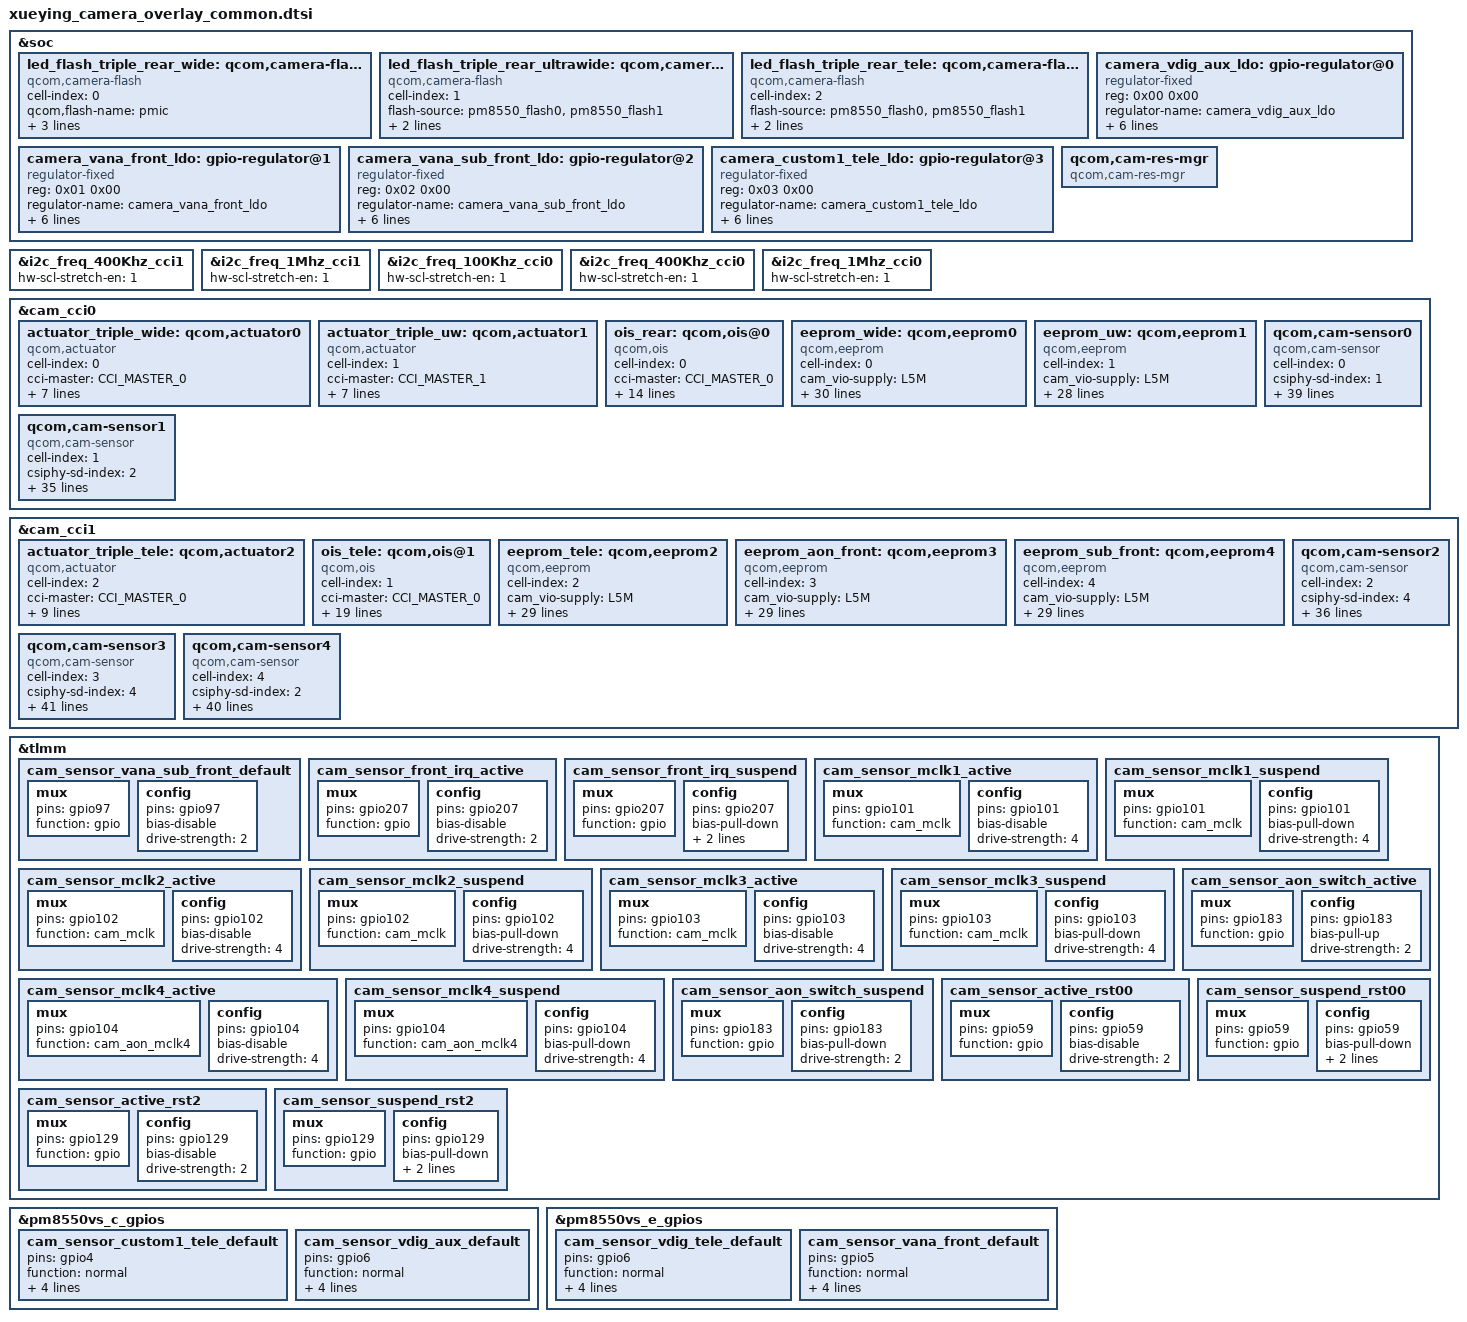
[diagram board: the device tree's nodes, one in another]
#include <dt-bindings/msm-camera.h>

&soc {
	led_flash_triple_rear_wide: qcom,camera-flash0 {
		cell-index = <0>;
		compatible = "qcom,camera-flash";
		qcom,flash-name = "pmic";
		flash-source = <&pm8550_flash0 &pm8550_flash1>;
		torch-source = <&pm8550_torch0 &pm8550_torch1>;
		switch-source = <&pm8550_switch2>;
		status = "ok";
	};

	led_flash_triple_rear_ultrawide: qcom,camera-flash1 {
		cell-index = <1>;
		compatible = "qcom,camera-flash";
		flash-source = <&pm8550_flash0 &pm8550_flash1>;
		torch-source = <&pm8550_torch0 &pm8550_torch1>;
		switch-source = <&pm8550_switch2>;
		status = "ok";
	};

	led_flash_triple_rear_tele: qcom,camera-flash2 {
		cell-index = <2>;
		compatible = "qcom,camera-flash";
		flash-source = <&pm8550_flash0 &pm8550_flash1>;
		torch-source = <&pm8550_torch0 &pm8550_torch1>;
		switch-source = <&pm8550_switch2>;
		status = "ok";
	};

	camera_vdig_aux_ldo: gpio-regulator@0 {
		compatible = "regulator-fixed";
		reg = <0x00 0x00>;
		regulator-name = "camera_vdig_aux_ldo";
		regulator-min-microvolt = <1120000>;
		regulator-max-microvolt = <1120000>;
		regulator-enable-ramp-delay = <135>;
		enable-active-high;
		gpio = <&pm8550vs_c_gpios 6 0>;
		pinctrl-names = "default";
		pinctrl-0 = <&cam_sensor_vdig_aux_default>;
		//vin-supply = <&S6G>;
	};

	camera_vana_front_ldo: gpio-regulator@1 {
		compatible = "regulator-fixed";
		reg = <0x01 0x00>;
		regulator-name = "camera_vana_front_ldo";
		regulator-min-microvolt = <2800000>;
		regulator-max-microvolt = <2800000>;
		regulator-enable-ramp-delay = <135>;
		enable-active-high;
		gpio = <&pm8550vs_e_gpios 5 0>;
		pinctrl-names = "default";
		pinctrl-0 = <&cam_sensor_vana_front_default>;
	};

	camera_vana_sub_front_ldo: gpio-regulator@2 {
		compatible = "regulator-fixed";
		reg = <0x02 0x00>;
		regulator-name = "camera_vana_sub_front_ldo";
		regulator-min-microvolt = <2800000>;
		regulator-max-microvolt = <2800000>;
		regulator-enable-ramp-delay = <135>;
		enable-active-high;
		gpio = <&tlmm 97 0>;
		pinctrl-names = "default";
		pinctrl-0 = <&cam_sensor_vana_sub_front_default>;
	};


    camera_custom1_tele_ldo: gpio-regulator@3 {
		compatible = "regulator-fixed";
		reg = <0x03 0x00>;
		regulator-name = "camera_custom1_tele_ldo";
		regulator-min-microvolt = <2800000>;
		regulator-max-microvolt = <2800000>;
		regulator-enable-ramp-delay = <135>;
		enable-active-high;
		gpio = <&pm8550vs_c_gpios 4 0>;
		pinctrl-names = "default";
		pinctrl-0 = <&cam_sensor_custom1_tele_default>;
	};

	qcom,cam-res-mgr {
		compatible = "qcom,cam-res-mgr";
		status = "ok";
	};
};


&i2c_freq_400Khz_cci1 {
    hw-scl-stretch-en = <1>;
};

&i2c_freq_1Mhz_cci1 {
    hw-scl-stretch-en = <1>;
};

&i2c_freq_100Khz_cci0 {
    hw-scl-stretch-en = <1>;
};

&i2c_freq_400Khz_cci0 {
    hw-scl-stretch-en = <1>;
};

&i2c_freq_1Mhz_cci0 {
    hw-scl-stretch-en = <1>;
};

&cam_cci0 {
	actuator_triple_wide: qcom,actuator0 {
		cell-index = <0>;
		compatible = "qcom,actuator";
		cci-master = <CCI_MASTER_0>;
		cam_vio-supply = <&L5M>;
		cam_vaf-supply = <&L6M>;
		regulator-names = "cam_vio", "cam_vaf";
		rgltr-cntrl-support;
		rgltr-min-voltage = <1800000 3000000>;
		rgltr-max-voltage = <1800000 3000000>;
		rgltr-load-current = <600000 300000>;
		status = "ok";
	};

	actuator_triple_uw: qcom,actuator1 {
		cell-index = <1>;
		compatible = "qcom,actuator";
		cci-master = <CCI_MASTER_1>;
		cam_vio-supply = <&L5M>;
		cam_vaf-supply = <&L6N>;
		regulator-names = "cam_vio", "cam_vaf";
		rgltr-cntrl-support;
		rgltr-min-voltage = <1800000 2800000>;
		rgltr-max-voltage = <1800000 2800000>;
		rgltr-load-current = <600000 300000>;
		status = "ok";
	};

	ois_rear: qcom,ois@0{
		cell-index = <0>;
		compatible = "qcom,ois";
		cci-master = <CCI_MASTER_0>;
		cam_vio-supply = <&L5M>;
		cam_v_custom2-supply = <&L7M>;
		cam_vaf-supply = <&L6M>;
		regulator-names = "cam_vio","cam_v_custom1", "cam_vaf";
		rgltr-cntrl-support;
		rgltr-min-voltage = <1800000 3000000 3000000>;
		rgltr-max-voltage = <1800000 3000000 3000000>;
		rgltr-load-current = <600000 600000 300000>;
		ois_gyro,position=<3>;
		ois_gyro,type=<3>;
		ois,type=<0>;
		ois,name="dw9828";
		ois,fw=<1>;
		status = "ok";
	};

	eeprom_wide: qcom,eeprom0 {
		cell-index = <0>;
		compatible = "qcom,eeprom";
		cam_vio-supply = <&L5M>;
		cam_vdig-supply = <&L1M>;
		cam_vana-supply = <&L3M>;
		cam_v_custom1-supply = <&L4M>;
		cam_vaf-supply = <&L6M>;
		cam_v_custom2-supply = <&L7M>;
		cam_clk-supply = <&cam_cc_titan_top_gdsc>;
		regulator-names = "cam_vio", "cam_vana", "cam_v_custom1", "cam_vdig", "cam_vaf",
		                  "cam_v_custom2", "cam_clk";
		rgltr-cntrl-support;
		rgltr-min-voltage = <1800000 2200000 2000000 840000 3000000 3000000 0>;
		rgltr-max-voltage = <1800000 2800000 2000000 920000 3000000 3000000 0>;
		rgltr-load-current = <600000 300000 300000 1200000 300000 600000 0>;
		gpio-no-mux = <0>;
		pinctrl-names = "cam_default", "cam_suspend";
		pinctrl-0 = <&cam_sensor_mclk2_active
			&cam_sensor_active_rst1>;
		pinctrl-1 = <&cam_sensor_mclk2_suspend
			&cam_sensor_suspend_rst1>;
		gpios = <&tlmm 102 0>,
			<&tlmm 117 0>;
		gpio-reset = <1>;
		gpio-req-tbl-num = <0 1>;
		gpio-req-tbl-flags = <1 0>;
		gpio-req-tbl-label = "CAMIF_MCLK2",
					"CAM_RESET1";
		cci-master = <CCI_MASTER_0>;
		clocks = <&camcc CAM_CC_MCLK2_CLK>;
		clock-names = "cam_clk";
		clock-cntl-level = "nominal";
		clock-rates = <19200000>;
		status = "ok";
	};

	eeprom_uw: qcom,eeprom1 {
		cell-index = <1>;
		compatible = "qcom,eeprom";
		cam_vio-supply = <&L5M>;
		cam_vdig-supply = <&L1N>;
		cam_vana-supply = <&L3N>;
		cam_v_custom1-supply = <&L5N>;
		cam_vaf-supply = <&L6N>;
		cam_clk-supply = <&cam_cc_titan_top_gdsc>;
		regulator-names = "cam_vio", "cam_vana", "cam_v_custom1",
			"cam_vdig", "cam_vaf", "cam_clk";
		rgltr-cntrl-support;
		rgltr-min-voltage = <1800000 2904000 1800000 1104000 2800000 0>;
		rgltr-max-voltage = <1800000 2904000 1800000 1104000 2800000 0>;
		rgltr-load-current = <600000 300000 600000 1200000 300000 0>;
		gpio-no-mux = <0>;
		pinctrl-names = "cam_default", "cam_suspend";
		pinctrl-0 = <&cam_sensor_mclk1_active
				 &cam_sensor_active_rst2>;
		pinctrl-1 = <&cam_sensor_mclk1_suspend
				 &cam_sensor_suspend_rst2>;
		gpios = <&tlmm 101 0>,
			<&tlmm 129 0>;
		gpio-reset = <1>;
		gpio-req-tbl-num = <0 1>;
		gpio-req-tbl-flags = <1 0>;
		gpio-req-tbl-label = "CAMIF_MCLK1",
					"CAM_RESET2";
		cci-master = <CCI_MASTER_1>;
		clocks = <&camcc CAM_CC_MCLK1_CLK>;
		clock-names = "cam_clk";
		clock-cntl-level = "nominal";
		clock-rates = <19200000>;
		status = "ok";
	};
    //main camera
	qcom,cam-sensor0 {
		cell-index = <0>;
		compatible = "qcom,cam-sensor";
		csiphy-sd-index = <1>;
		sensor-position-roll = <90>;
		sensor-position-pitch = <0>;
		sensor-position-yaw = <180>;
		eeprom-src = <&eeprom_wide>;
		actuator-src = <&actuator_triple_wide>;
		led-flash-src = <&led_flash_triple_rear_wide>;
		ois-src = <&ois_rear>;
		cam_vio-supply = <&L5M>;
		cam_vdig-supply = <&L1M>;
		cam_vana-supply = <&L3M>;
		cam_v_custom1-supply = <&L4M>;
		cam_vaf-supply = <&L6M>;
		cam_v_custom2-supply = <&L7M>;
		cam_clk-supply = <&cam_cc_titan_top_gdsc>;
		regulator-names = "cam_vio", "cam_vana", "cam_v_custom1", "cam_vdig", "cam_vaf",
		                  "cam_v_custom2", "cam_clk";
		rgltr-cntrl-support;
		rgltr-min-voltage = <1800000 2800000 2000000 840000 3000000 3000000 0>;
		rgltr-max-voltage = <1800000 2800000 2000000 840000 3000000 3000000 0>;
		rgltr-load-current = <600000 300000 300000 1200000 300000 600000 0>;
		gpio-no-mux = <0>;
		pinctrl-names = "cam_default", "cam_suspend";
		pinctrl-0 = <&cam_sensor_mclk2_active
			&cam_sensor_active_rst1>;
		pinctrl-1 = <&cam_sensor_mclk2_suspend
			&cam_sensor_suspend_rst1>;
		gpios = <&tlmm 102 0>,
			<&tlmm 117 0>;
		gpio-reset = <1>;
		gpio-req-tbl-num = <0 1>;
		gpio-req-tbl-flags = <1 0>;
		gpio-req-tbl-label = "CAMIF_MCLK2",
					"CAM_RESET1";
		cci-master = <CCI_MASTER_0>;
		clocks = <&camcc CAM_CC_MCLK2_CLK>;
		clock-names = "cam_clk";
		clock-cntl-level = "nominal";
		clock-rates = <19200000>;
		is-support-laser = <1>;
		status = "ok";
	};
    //wide camera
	qcom,cam-sensor1 {
		cell-index = <1>;
		compatible = "qcom,cam-sensor";
		csiphy-sd-index = <2>;
		sensor-position-roll = <90>;
		sensor-position-pitch = <0>;
		sensor-position-yaw = <180>;
		eeprom-src = <&eeprom_uw>;
		actuator-src = <&actuator_triple_uw>;
		led-flash-src = <&led_flash_triple_rear_ultrawide>;
		cam_vio-supply = <&L5M>;
		cam_vdig-supply = <&L1N>;
		cam_vana-supply = <&L3N>;
		cam_v_custom1-supply = <&L5N>;
		cam_vaf-supply = <&L6N>;
		cam_clk-supply = <&cam_cc_titan_top_gdsc>;
		regulator-names = "cam_vio", "cam_vana", "cam_v_custom1",
			"cam_vdig", "cam_vaf", "cam_clk";
		rgltr-cntrl-support;
		rgltr-min-voltage = <1800000 2904000 1800000 1104000 2800000 0>;
		rgltr-max-voltage = <1800000 2904000 1800000 1104000 2800000 0>;
		rgltr-load-current = <600000 300000 600000 1200000 300000 0>;
		gpio-no-mux = <0>;
		pinctrl-names = "cam_default", "cam_suspend";
		pinctrl-0 = <&cam_sensor_mclk1_active
				 &cam_sensor_active_rst2>;
		pinctrl-1 = <&cam_sensor_mclk1_suspend
				 &cam_sensor_suspend_rst2>;
		gpios = <&tlmm 101 0>,
			<&tlmm 129 0>;
		gpio-reset = <1>;
		gpio-req-tbl-num = <0 1>;
		gpio-req-tbl-flags = <1 0>;
		gpio-req-tbl-label = "CAMIF_MCLK1",
					"CAM_RESET2";
		cci-master = <CCI_MASTER_1>;
		clocks = <&camcc CAM_CC_MCLK1_CLK>;
		clock-names = "cam_clk";
		clock-cntl-level = "nominal";
		clock-rates = <19200000>;
		status = "ok";
	};

};

&cam_cci1 {
	actuator_triple_tele: qcom,actuator2{
		cell-index = <2>;
		compatible = "qcom,actuator";
		cci-master = <CCI_MASTER_0>;
		cam_vio-supply = <&L5M>;
		cam_v_custom1-supply = <&camera_custom1_tele_ldo>;
		cam_vaf-supply = <&L7N>;
		regulator-names = "cam_vio", "cam_v_custom1","cam_vaf";
		rgltr-cntrl-support;
		rgltr-min-voltage = <1800000 2800000 2800000>;
		rgltr-max-voltage = <1800000 2800000 2800000>;
		rgltr-load-current = <600000 600000 600000>;
		status = "ok";
	};

	ois_tele: qcom,ois@1{
		cell-index = <1>;
		compatible = "qcom,ois";
		cci-master = <CCI_MASTER_0>;
		cam_vio-supply = <&L5M>;
		cam_v_custom1-supply = <&camera_custom1_tele_ldo>;
		cam_vaf-supply = <&L7N>;
		regulator-names = "cam_vio", "cam_v_custom1", "cam_vaf";
		rgltr-cntrl-support;
		rgltr-min-voltage = <1800000 2800000 2800000>;
		rgltr-max-voltage = <1800000 2800000 2800000>;
		rgltr-load-current = <600000 600000 600000>;
		ois_gyro,position=<3>;
		ois_gyro,type=<0>;
		ois,type=<1>;
		ois,name="sem1217s";
		ois_module,vendor=<1>;
		ois_actuator,vednor=<2>;
		ois,fw=<1>;
		download,fw=<1>;
		ois_eis_function = <6>;
		actuator_ois_eeprom_merge = <1>;
		status = "ok";
	};

	eeprom_tele: qcom,eeprom2 {
		cell-index = <2>;
		compatible = "qcom,eeprom";
		cam_vio-supply = <&L5M>;
		cam_vdig-supply = <&L2N>;
		cam_vana-supply = <&L4N>;
		cam_v_custom1-supply = <&camera_custom1_tele_ldo>;//ois
		cam_vaf-supply = <&L7N>;
		cam_clk-supply = <&cam_cc_titan_top_gdsc>;
		regulator-names = "cam_vio", "cam_vana", "cam_vdig", "cam_vaf", "cam_v_custom1","cam_clk";
		rgltr-cntrl-support;
		rgltr-min-voltage = <1800000 2904000 1104000 2800000 2800000 0>;
		rgltr-max-voltage = <1800000 2904000 1104000 2800000 2800000 0>;
		rgltr-load-current = <600000 300000 1200000 600000 600000 0>;
		gpio-no-mux = <0>;
		pinctrl-names = "cam_default", "cam_suspend";
		pinctrl-0 = <&cam_sensor_mclk0_active
				 &cam_sensor_active_rst00>;
		pinctrl-1 = <&cam_sensor_mclk0_suspend
				 &cam_sensor_suspend_rst00>;
		gpios = <&tlmm 100 0>,
			<&tlmm 59 0>;
		gpio-reset = <1>;
		gpio-req-tbl-num = <0 1>;
		gpio-req-tbl-flags = <1 0>;
		gpio-req-tbl-label = "CAMIF_MCLK0",
					"CAM_RESET00";
		cci-master = <CCI_MASTER_0>;
		clocks = <&camcc CAM_CC_MCLK0_CLK>;
		clock-names = "cam_clk";
		clock-cntl-level = "nominal";
		clock-rates = <19200000>;
		actuator_ois_eeprom_merge = <1>;
		status = "ok";
	};

	eeprom_aon_front: qcom,eeprom3 {
		cell-index = <3>;
		compatible = "qcom,eeprom";
		cam_vio-supply = <&L5M>;
		cam_vana-supply = <&camera_vana_front_ldo>;
		cam_vdig-supply = <&L2M>;
		cam_clk-supply = <&cam_cc_titan_top_gdsc>;
		regulator-names = "cam_vio", "cam_vana", "cam_vdig", "cam_clk";
		rgltr-cntrl-support;
		rgltr-min-voltage = <1800000 2800000 1120000 0>;
		rgltr-max-voltage = <1800000 2800000 1120000 0>;
		rgltr-load-current = <600000 300000 1200000 0>;
		gpio-no-mux = <0>;
		pinctrl-names = "cam_default", "cam_suspend";
		pinctrl-0 = <&cam_sensor_mclk4_active
				 &cam_sensor_active_rst4
				 &cam_sensor_aon_switch_active
				 &cam_sensor_front_irq_active>;
		pinctrl-1 = <&cam_sensor_mclk4_suspend
				 &cam_sensor_suspend_rst4
				 &cam_sensor_aon_switch_suspend
				 &cam_sensor_front_irq_suspend>;
		gpios = <&tlmm 104 0>,
			<&tlmm 120 0>,
			<&tlmm 183 0>,
			<&tlmm 207 0>;
		gpio-reset = <1>;
		gpio-custom1 = <2>;
		gpio-req-tbl-num = <0 1 2 3>;
		gpio-req-tbl-flags = <1 0 0 0>;
		gpio-req-tbl-label = "CAMIF_MCLK4",
					"CAM_RESET4",
					"CAM_AON_SWITCH",
					"CAM_AON_IRQ";
		cci-master = <CCI_MASTER_1>;
		clocks = <&camcc CAM_CC_MCLK4_CLK>;
		clock-names = "cam_clk";
		clock-cntl-level = "nominal";
		clock-rates = <19200000>;
		status = "ok";
	};

	eeprom_sub_front: qcom,eeprom4 {
		cell-index = <4>;
		compatible = "qcom,eeprom";
		cam_vio-supply = <&L5M>;
		cam_vana-supply = <&camera_vana_sub_front_ldo>;
		cam_vdig-supply = <&camera_vdig_aux_ldo>;
		cam_clk-supply = <&cam_cc_titan_top_gdsc>;
		regulator-names = "cam_vio", "cam_vana", "cam_vdig", "cam_clk";
		rgltr-cntrl-support;
		rgltr-min-voltage = <1800000 2800000 1120000 0>;
		rgltr-max-voltage = <1800000 2800000 1120000 0>;
		rgltr-load-current = <600000 300000 1200000 0>;
		gpio-no-mux = <0>;
		pinctrl-names = "cam_default", "cam_suspend";
		pinctrl-0 = <&cam_sensor_mclk4_active
				 &cam_sensor_active_rst4
				 &cam_sensor_aon_switch_active
				 &cam_sensor_front_irq_active>;
		pinctrl-1 = <&cam_sensor_mclk4_suspend
				 &cam_sensor_suspend_rst4
				 &cam_sensor_aon_switch_suspend
				 &cam_sensor_front_irq_suspend>;
		gpios = <&tlmm 104 0>,
			<&tlmm 120 0>,
			<&tlmm 183 0>,
			<&tlmm 207 0>;
		gpio-reset = <1>;
		gpio-custom1 = <2>;
		gpio-req-tbl-num = <0 1 2 3>;
		gpio-req-tbl-flags = <1 0 0 0>;
		gpio-req-tbl-label = "CAMIF_MCLK4",
					"CAM_RESET4",
					"CAM_AON_SWITCH",
					"CAM_AON_IRQ";
		cci-master = <CCI_MASTER_1>;
		clocks = <&camcc CAM_CC_MCLK4_CLK>;
		clock-names = "cam_clk";
		clock-cntl-level = "nominal";
		clock-rates = <19200000>;
		status = "ok";
	};

	qcom,cam-sensor2 {//tele camera
		cell-index = <2>;
		compatible = "qcom,cam-sensor";
		csiphy-sd-index = <4>;
		sensor-position-roll = <90>;
		sensor-position-pitch = <0>;
		sensor-position-yaw = <180>;
		eeprom-src = <&eeprom_tele>;
		actuator-src = <&actuator_triple_tele>;
		led-flash-src = <&led_flash_triple_rear_tele>;
		ois-src = <&ois_tele>;
		cam_vio-supply = <&L5M>;
		cam_vdig-supply = <&L2N>;
		cam_vana-supply = <&L4N>;
		cam_v_custom1-supply = <&camera_custom1_tele_ldo>;//ois
		cam_vaf-supply = <&L7N>;
		cam_clk-supply = <&cam_cc_titan_top_gdsc>;
		regulator-names = "cam_vio", "cam_vana", "cam_vdig", "cam_vaf", "cam_v_custom1","cam_clk";
		rgltr-cntrl-support;
		rgltr-min-voltage = <1800000 2800000 1104000 2800000 2800000 0>;
		rgltr-max-voltage = <1800000 2800000 1104000 2800000 2800000 0>;
		rgltr-load-current = <600000 300000 1200000 600000 600000 0>;
		gpio-no-mux = <0>;
		pinctrl-names = "cam_default", "cam_suspend";
		pinctrl-0 = <&cam_sensor_mclk0_active
				 &cam_sensor_active_rst00>;
		pinctrl-1 = <&cam_sensor_mclk0_suspend
				 &cam_sensor_suspend_rst00>;
		gpios = <&tlmm 100 0>,
			<&tlmm 59 0>;
		gpio-reset = <1>;
		gpio-req-tbl-num = <0 1>;
		gpio-req-tbl-flags = <1 0>;
		gpio-req-tbl-label = "CAMIF_MCLK0",
					"CAM_RESET00";
		cci-master = <CCI_MASTER_0>;
		clocks = <&camcc CAM_CC_MCLK0_CLK>;
		clock-names = "cam_clk";
		clock-cntl-level = "nominal";
		clock-rates = <19200000>;
		status = "ok";
	};

	// front main
	qcom,cam-sensor3 {
		cell-index = <3>;
		compatible = "qcom,cam-sensor","zeku,aon-sensor";
		csiphy-sd-index = <4>;
		sensor-position-roll = <270>;
		sensor-position-pitch = <0>;
		sensor-position-yaw = <180>;
		eeprom-src = <&eeprom_aon_front>;
		cam_vio-supply = <&L5M>;
		cam_vana-supply = <&camera_vana_front_ldo>;
		cam_vdig-supply = <&L2M>;
		cam_v_custom2-supply = <&camera_vana_sub_front_ldo>;
		cam_v_custom1-supply = <&camera_vdig_aux_ldo>;
		cam_clk-supply = <&cam_cc_titan_top_gdsc>;
		regulator-names = "cam_vio", "cam_vana", "cam_vdig", "cam_v_custom2", "cam_v_custom1", "cam_clk";
		rgltr-cntrl-support;
		rgltr-min-voltage = <1800000 2800000 1120000 2800000 1120000 0>;
		rgltr-max-voltage = <1800000 2800000 1120000 2800000 1120000 0>;
		rgltr-load-current = <600000 300000 1200000 300000 1200000 0>;
		gpio-no-mux = <0>;
		pinctrl-names = "cam_default", "cam_suspend";
		pinctrl-0 = <&cam_sensor_mclk4_active
				 &cam_sensor_active_rst4
				 &cam_sensor_aon_switch_active
				 &cam_sensor_front_irq_active>;
		pinctrl-1 = <&cam_sensor_mclk4_suspend
				 &cam_sensor_suspend_rst4
				 &cam_sensor_aon_switch_suspend
				 &cam_sensor_front_irq_suspend>;
		gpios = <&tlmm 104 0>,
			<&tlmm 120 0>,
			<&tlmm 183 0>,
			<&tlmm 207 0>;
		gpio-reset = <1>;
		gpio-custom1 = <2>;
		gpio-req-tbl-num = <0 1 2 3>;
		gpio-req-tbl-flags = <1 0 0 0>;
		gpio-req-tbl-label = "CAMIF_MCLK4",
					"CAM_RESET4",
					"CAM_AON_SWITCH",
					"CAM_AON_IRQ";
		cci-master = <CCI_MASTER_1>;
        //qcom-aon-irq-gpio = <&tlmm 207 0>;
		clocks = <&camcc CAM_CC_MCLK4_CLK>;
		clock-names = "cam_clk";
		clock-cntl-level = "nominal";
		clock-rates = <19200000>;
		is-gpio-reuse = <1>;
		status = "ok";
	};
	// front sub
	qcom,cam-sensor4 {
		cell-index = <4>;
		compatible = "qcom,cam-sensor","zeku,aon-auxsensor";
		csiphy-sd-index = <2>;
		sensor-position-roll = <270>;
		sensor-position-pitch = <0>;
		sensor-position-yaw = <180>;
		eeprom-src = <&eeprom_sub_front>;
		cam_vio-supply = <&L5M>;
		cam_vana-supply = <&camera_vana_sub_front_ldo>;
		cam_vdig-supply = <&camera_vdig_aux_ldo>;
		cam_v_custom2-supply = <&camera_vana_front_ldo>;
		cam_v_custom1-supply = <&L2M>;
		cam_clk-supply = <&cam_cc_titan_top_gdsc>;
		regulator-names = "cam_vio", "cam_vana", "cam_vdig", "cam_v_custom2", "cam_v_custom1", "cam_clk";
		rgltr-cntrl-support;
		rgltr-min-voltage = <1800000 2800000 1120000 2800000 1120000 0>;
		rgltr-max-voltage = <1800000 2800000 1120000 2800000 1120000 0>;
		rgltr-load-current = <600000 300000 1200000 300000 1200000 0>;
		gpio-no-mux = <0>;
		pinctrl-names = "cam_default", "cam_suspend";
		pinctrl-0 = <&cam_sensor_mclk4_active
				 &cam_sensor_active_rst4
				 &cam_sensor_aon_switch_active
				 &cam_sensor_front_irq_active>;
		pinctrl-1 = <&cam_sensor_mclk4_suspend
				 &cam_sensor_suspend_rst4
				 &cam_sensor_aon_switch_suspend
				 &cam_sensor_front_irq_suspend>;
		gpios = <&tlmm 104 0>,
			<&tlmm 120 0>,
			<&tlmm 183 0>,
			<&tlmm 207 0>;
		gpio-reset = <1>;
		gpio-custom1 = <2>;
		gpio-req-tbl-num = <0 1 2 3>;
		gpio-req-tbl-flags = <1 0 0 0>;
		gpio-req-tbl-label = "CAMIF_MCLK4",
					"CAM_RESET4",
					"CAM_AON_SWITCH",
					"CAM_AON_IRQ";
		cci-master = <CCI_MASTER_1>;
        //qcom-aon-irq-gpio = <&tlmm 207 0>;
		clocks = <&camcc CAM_CC_MCLK4_CLK>;
		clock-names = "cam_clk";
		clock-cntl-level = "nominal";
		clock-rates = <19200000>;
		is-gpio-reuse = <1>;
		status = "ok";
	};

};

&tlmm {
	cam_sensor_vana_sub_front_default: cam_sensor_vana_sub_front_default {
		/* FRONT SUB VANA */
		mux {
			pins = "gpio97";
			function = "gpio";
		};

		config {
			pins = "gpio97";
			bias-disable; /* No PULL */
			drive-strength = <2>; /* 2 MA */
		};
	};

	cam_sensor_front_irq_active: cam_sensor_front_irq_active {
		/* FRONT IRQ */
		mux {
			pins = "gpio207";
			function = "gpio";
		};

		config {
			pins = "gpio207";
			bias-disable; /* No PULL */
			drive-strength = <2>; /* 2 MA */
		};
	};

	cam_sensor_front_irq_suspend: cam_sensor_front_irq_suspend {
		/* FRONT IRQ */
		mux {
			pins = "gpio207";
			function = "gpio";
		};

		config {
			pins = "gpio207";
			bias-pull-down; /* PULL DOWN */
			drive-strength = <2>; /* 2 MA */
			output-low;
		};
	};

	cam_sensor_mclk1_active: cam_sensor_mclk1_active {
		/* MCLK1 */
		mux {
			pins = "gpio101";
			function = "cam_mclk";
		};

		config {
			pins = "gpio101";
			bias-disable; /* No PULL */
			drive-strength = <4>; /* 2 MA */
		};
	};

	cam_sensor_mclk1_suspend: cam_sensor_mclk1_suspend {
		/* MCLK1 */
		mux {
			pins = "gpio101";
			function = "cam_mclk";
		};

		config {
			pins = "gpio101";
			bias-pull-down; /* PULL DOWN */
			drive-strength = <4>; /* 2 MA */
		};
	};

	cam_sensor_mclk2_active: cam_sensor_mclk2_active {
		/* MCLK2 */
		mux {
			pins = "gpio102";
			function = "cam_mclk";
		};

		config {
			pins = "gpio102";
			bias-disable; /* No PULL */
			drive-strength = <4>; /* 2 MA */
		};
	};

	cam_sensor_mclk2_suspend: cam_sensor_mclk2_suspend {
		/* MCLK2 */
		mux {
			pins = "gpio102";
			function = "cam_mclk";
		};

		config {
			pins = "gpio102";
			bias-pull-down; /* PULL DOWN */
			drive-strength = <4>; /* 2 MA */
		};
	};

	cam_sensor_mclk3_active: cam_sensor_mclk3_active {
		/* MCLK3 */
		mux {
			pins = "gpio103";
			function = "cam_mclk";
		};

		config {
			pins = "gpio103";
			bias-disable; /* No PULL */
			drive-strength = <4>; /* 2 MA */
		};
	};

	cam_sensor_mclk3_suspend: cam_sensor_mclk3_suspend {
		/* MCLK3 */
		mux {
			pins = "gpio103";
			function = "cam_mclk";
		};

		config {
			pins = "gpio103";
			bias-pull-down; /* PULL DOWN */
			drive-strength = <4>; /* 2 MA */
		};
	};

	cam_sensor_mclk4_active: cam_sensor_mclk4_active {
		/* MCLK4 */
		mux {
			pins = "gpio104";
			function = "cam_aon_mclk4";
		};

		config {
			pins = "gpio104";
			bias-disable; /* No PULL */
			drive-strength = <4>; /* 2 MA */
		};
	};

	cam_sensor_mclk4_suspend: cam_sensor_mclk4_suspend {
		/* MCLK4 */
		mux {
			pins = "gpio104";
			function = "cam_aon_mclk4";
		};

		config {
			pins = "gpio104";
			bias-pull-down; /* PULL DOWN */
			drive-strength = <4>; /* 2 MA */
		};
	};

	cam_sensor_aon_switch_active: cam_sensor_aon_switch_active {
		/* AON SWITCH */
		mux {
			pins = "gpio183";
			function = "gpio";
		};

		config {
			pins = "gpio183";
			bias-pull-up; /* PULL UP */
			drive-strength = <2>; /* 2 MA */
		};
	};

	cam_sensor_aon_switch_suspend: cam_sensor_aon_switch_suspend {
		/* AON SWITCH */
		mux {
			pins = "gpio183";
			function = "gpio";
		};

		config {
			pins = "gpio183";
			bias-pull-down; /* PULL DOWN */
			drive-strength = <2>; /* 2 MA */
		};
	};

	cam_sensor_active_rst00: cam_sensor_active_rst00 {  //sensor2 use
		mux {
			pins = "gpio59";
			function = "gpio";
		};

		config {
			pins = "gpio59";
			bias-disable; /* No PULL */
			drive-strength = <2>; /* 2 MA */
		};
	};

	cam_sensor_suspend_rst00: cam_sensor_suspend_rst00 {
		mux {
			pins = "gpio59";
			function = "gpio";
		};

		config {
			pins = "gpio59";
			bias-pull-down; /* PULL DOWN */
			drive-strength = <2>; /* 2 MA */
			output-low;
		};
	};

        cam_sensor_active_rst2: cam_sensor_active_rst2 {
                mux {
                        pins = "gpio129";
                        function = "gpio";
                };

                config {
                        pins = "gpio129";
                        bias-disable; /* No PULL */
                        drive-strength = <2>; /* 2 MA */
                };
        };

        cam_sensor_suspend_rst2: cam_sensor_suspend_rst2 {
                mux {
                        pins = "gpio129";
                        function = "gpio";
                };

                config {
                        pins = "gpio129";
                        bias-pull-down; /* PULL DOWN */
                        drive-strength = <2>; /* 2 MA */
                        output-low;
                };
        };
};

&pm8550vs_c_gpios {
		cam_sensor_custom1_tele_default: cam_sensor_custom1_tele_default {
			pins = "gpio4";
			function = "normal";
			input-disable;
			output-low;
			power-source = <1>; /* 1.8V */
			qcom,drive-strength = <2>;
		};
};
&pm8550vs_c_gpios {
		cam_sensor_vdig_aux_default: cam_sensor_vdig_aux_default {
			pins = "gpio6";
			function = "normal";
			input-disable;
			output-low;
			power-source = <1>; /* 1.8V */
			qcom,drive-strength = <2>;
		};
};

&pm8550vs_e_gpios {
		cam_sensor_vdig_tele_default: cam_sensor_vdig_tele_default {
			pins = "gpio6";
			function = "normal";
			input-disable;
			output-low;
			power-source = <1>; /* 1.8V */
			qcom,drive-strength = <2>;
		};
};
&pm8550vs_e_gpios {
		cam_sensor_vana_front_default: cam_sensor_vana_front_default {
			pins = "gpio5";
			function = "normal";
			input-disable;
			output-low;
			power-source = <1>; /* 1.8V */
			qcom,drive-strength = <2>;
		};
};
